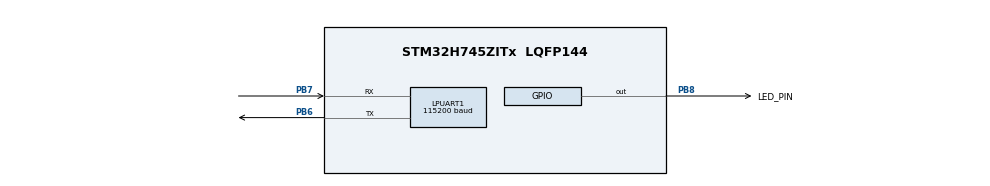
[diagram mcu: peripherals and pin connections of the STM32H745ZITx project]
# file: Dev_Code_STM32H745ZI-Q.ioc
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CORTEX_M7.default_mode_Activation=1
CortexM4.IPs=FATFS_M4\:I,FREERTOS_M4\:I,IWDG2\:I,RCC,WWDG2\:I,DMA,BDMA,MDMA,NVIC2\:I,USART3,ETH,DEBUG,PDM2PCM_M4\:I,PWR,RESMGR_UTILITY,SYS_M4\:I,USB_DEVICE_M4\:I,USB_HOST_M4\:I,CORTEX_M4\:I,GPIO,OPENAMP_M4\:I,VREFBUF,NUCLEO-H745ZI-Q\:I
CortexM7.IPs=FATFS_M7\:I,FREERTOS_M7\:I,IWDG1\:I,RCC\:I,WWDG1\:I,DMA\:I,BDMA\:I,MDMA\:I,NVIC1\:I,SYS\:I,USART3\:I,USB_OTG_FS\:I,ETH\:I,CORTEX_M7\:I,DEBUG\:I,PDM2PCM_M7\:I,PWR\:I,RESMGR_UTILITY\:I,USB_DEVICE_M7\:I,USB_HOST_M7\:I,GPIO\:I,OPENAMP_M7\:I,VREFBUF\:I,LPUART1\:I
CortexM7.Pins=PB8
LPUART1.BaudRate=115200
Mcu.Family=STM32H7
Mcu.Name=STM32H745ZITx
Mcu.Package=LQFP144
NUCLEO-H745ZI-Q.BUTTON=1
NUCLEO-H745ZI-Q.Bsp_Common_DEMO=true
NUCLEO-H745ZI-Q.LD1=true
NUCLEO-H745ZI-Q.LD2=true
NUCLEO-H745ZI-Q.LD3=true
NUCLEO-H745ZI-Q.VCP=true
NVIC1.PriorityGroup=NVIC_PRIORITYGROUP_4
NVIC2.EXTI15_10_IRQn=true\:0\:0\:false\:false\:true\:false\:true\:true
NVIC2.PriorityGroup=NVIC_PRIORITYGROUP_4
PB6.Mode=Asynchronous
PB6.PinAttribute=CortexM7
PB6.Signal=LPUART1_TX
PB7.Mode=Asynchronous
PB7.PinAttribute=CortexM7
PB7.Signal=LPUART1_RX
PB8.GPIO_Label=LED_PIN
PB8.GPIO_ModeDefaultOutputPP=GPIO_MODE_OUTPUT_PP
PB8.PinAttribute=CortexM7
PB8.PinState=GPIO_PIN_RESET
PB8.Signal=GPIO_Output
PC14-OSC32_IN\ (OSC32_IN).PinAttribute=Free
PC14-OSC32_IN\ (OSC32_IN).Signal=RCC_OSC32_IN
PC15-OSC32_OUT\ (OSC32_OUT).PinAttribute=Free
PC15-OSC32_OUT\ (OSC32_OUT).Signal=RCC_OSC32_OUT
PD8.Signal=USART3_TX
PD9.Signal=USART3_RX
PH0-OSC_IN\ (PH0).PinAttribute=Free
PH0-OSC_IN\ (PH0).Signal=RCC_OSC_IN
PH1-OSC_OUT\ (PH1).PinAttribute=Free
PH1-OSC_OUT\ (PH1).Signal=RCC_OSC_OUT
ProjectManager.HeapSize=M4-0x200,M7-0x200
ProjectManager.StackSize=M4-0x400,M7-0x400
ProjectManager.TargetToolchain=STM32CubeIDE
RCC.ADCFreq_Value=129000000
RCC.APB1Freq_Value=64000000
RCC.APB2Freq_Value=64000000
RCC.APB3Freq_Value=32000000
RCC.APB4Freq_Value=64000000
RCC.CortexFreq_Value=64000000
RCC.D1PPRE=RCC_APB3_DIV2
RCC.DIVM1=18
RCC.DIVM3=22
RCC.DIVN3=169
RCC.DIVQ3=4
RCC.HCLKFreq_Value=64000000
RCC.PLL2FRACN=0
RCC.PLL3FRACN=0
RCC.PLLFRACN=0
RCC.SYSCLKFreq_VALUE=64000000
RCC.SupplySource=PWR_DIRECT_SMPS_SUPPLY
RCC.USBCLockSelection=RCC_USBCLKSOURCE_PLL3
RCC.USBFreq_Value=122909090.9090909
VP_NUCLEO-H745ZI-Q_VS_BSP_COMMON.Mode=COMMON
VP_SYS_M4_VS_Systick.Mode=SysTick
board=NUCLEO-H745ZI-Q

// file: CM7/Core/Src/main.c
/* USER CODE BEGIN Header */
/**
  ******************************************************************************
  * @file           : main.c
  * @brief          : Main program body
  ******************************************************************************
  * @attention
  *
  * Copyright (c) 2026 STMicroelectronics.
  * All rights reserved.
  *
  * This software is licensed under terms that can be found in the LICENSE file
  * in the root directory of this software component.
  * If no LICENSE file comes with this software, it is provided AS-IS.
  *
  ******************************************************************************
  */
/* USER CODE END Header */
#include "main.h"

/* USER CODE BEGIN PD */

/* DUAL_CORE_BOOT_SYNC_SEQUENCE: Define for dual core boot synchronization    */
/*                             demonstration code based on hardware semaphore */
/* This define is present in both CM7/CM4 projects                            */
/* To comment when developping/debugging on a single core                     */
#define DUAL_CORE_BOOT_SYNC_SEQUENCE

#if defined(DUAL_CORE_BOOT_SYNC_SEQUENCE)
#ifndef HSEM_ID_0
#define HSEM_ID_0 (0U) /* HW semaphore 0*/
#endif
#endif /* DUAL_CORE_BOOT_SYNC_SEQUENCE */

/* USER CODE END PD */

UART_HandleTypeDef hlpuart1;

uint8_t rx_buff[10]; // Buffer to store received data

char msg1[] = "I got your Message!\r\n";
char msg2[] = "I didn't get a message\r\n";

unsigned int LED_ON = 1;
unsigned int LED_OFF = 0;

void SystemClock_Config(void);
static void MPU_Config(void);
static void MX_GPIO_Init(void);
static void MX_LPUART1_UART_Init(void);

int main(void)
{

/* USER CODE BEGIN Boot_Mode_Sequence_0 */
#if defined(DUAL_CORE_BOOT_SYNC_SEQUENCE)
  int32_t timeout;
#endif /* DUAL_CORE_BOOT_SYNC_SEQUENCE */
/* USER CODE END Boot_Mode_Sequence_0 */

  /* MPU Configuration--------------------------------------------------------*/
  MPU_Config();

/* USER CODE BEGIN Boot_Mode_Sequence_1 */
#if defined(DUAL_CORE_BOOT_SYNC_SEQUENCE)
  /* Wait until CPU2 boots and enters in stop mode or timeout*/
  timeout = 0xFFFF;
  while((__HAL_RCC_GET_FLAG(RCC_FLAG_D2CKRDY) != RESET) && (timeout-- > 0));
  if ( timeout < 0 )
  {
  Error_Handler();
  }
#endif /* DUAL_CORE_BOOT_SYNC_SEQUENCE */
/* USER CODE END Boot_Mode_Sequence_1 */
  /* MCU Configuration--------------------------------------------------------*/

  /* Reset of all peripherals, Initializes the Flash interface and the Systick. */
  HAL_Init();

  /* Configure the system clock */
  SystemClock_Config();
/* USER CODE BEGIN Boot_Mode_Sequence_2 */
#if defined(DUAL_CORE_BOOT_SYNC_SEQUENCE)
/* When system initialization is finished, Cortex-M7 will release Cortex-M4 by means of
HSEM notification */
/*HW semaphore Clock enable*/
__HAL_RCC_HSEM_CLK_ENABLE();
/*Take HSEM */
HAL_HSEM_FastTake(HSEM_ID_0);
/*Release HSEM in order to notify the CPU2(CM4)*/
HAL_HSEM_Release(HSEM_ID_0,0);
/* wait until CPU2 wakes up from stop mode */
timeout = 0xFFFF;
while((__HAL_RCC_GET_FLAG(RCC_FLAG_D2CKRDY) == RESET) && (timeout-- > 0));
if ( timeout < 0 )
{
Error_Handler();
}
#endif /* DUAL_CORE_BOOT_SYNC_SEQUENCE */
/* USER CODE END Boot_Mode_Sequence_2 */

  /* Initialize all configured peripherals */
  MX_GPIO_Init();
  MX_LPUART1_UART_Init();

  /* USER CODE BEGIN 2 */

  GPIO_InitTypeDef GPIO_InitStruct = {0};
  GPIO_InitStruct.Pin = GPIO_PIN_8;           // Change pin as needed
  GPIO_InitStruct.Mode = GPIO_MODE_OUTPUT_PP;
  GPIO_InitStruct.Pull = GPIO_NOPULL;
  GPIO_InitStruct.Speed = GPIO_SPEED_FREQ_LOW;
  HAL_GPIO_Init(GPIOB, &GPIO_InitStruct);     // Change port as needed

//  HAL_GPIO_WritePin(LED_PIN_GPIO_Port, LED_PIN_Pin, 1);

  /* USER CODE END 2 */

  /* Infinite loop */
  /* USER CODE BEGIN WHILE */
  while (1)
  {
//	if (HAL_UART_Receive(&hlpuart1, rx_buff, 10, HAL_MAX_DELAY) == HAL_OK){
//
////		HAL_GPIO_TogglePin(LED_PIN_GPIO_Port, LED_PIN_Pin);
//		HAL_GPIO_WritePin(LED_PIN_GPIO_Port, LED_PIN_Pin, 1);
//
////	     HAL_UART_Transmit(&huartX, rx_buff, 10, HAL_MAX_DELAY);
//
////		HAL_UART_Transmit(&hlpuart1, (uint8_t*)msg1, strlen(msg1), HAL_MAX_DELAY);
//
//
//	}
//	else{

//  }

	HAL_GPIO_WritePin(LED_PIN_GPIO_Port, LED_PIN_Pin, 1);

	HAL_UART_Transmit(&hlpuart1, (uint8_t*)"1\r\n", 3, HAL_MAX_DELAY);

	HAL_Delay(100);

	HAL_UART_Transmit(&hlpuart1, (uint8_t*)"0\r\n", 3, HAL_MAX_DELAY);

	HAL_GPIO_WritePin(LED_PIN_GPIO_Port, LED_PIN_Pin, 0);

	HAL_Delay(100);

//	 CppMain();// will run until the CppMain code returns from the loop in which will return to here and then terminate the program completely.
////
//

    /* USER CODE END WHILE */

  }
}

void SystemClock_Config(void)
{
  RCC_OscInitTypeDef RCC_OscInitStruct = {0};
  RCC_ClkInitTypeDef RCC_ClkInitStruct = {0};

  /** Supply configuration update enable
  */
  HAL_PWREx_ConfigSupply(PWR_DIRECT_SMPS_SUPPLY);

  /** Configure the main internal regulator output voltage
  */
  __HAL_PWR_VOLTAGESCALING_CONFIG(PWR_REGULATOR_VOLTAGE_SCALE3);

  while(!__HAL_PWR_GET_FLAG(PWR_FLAG_VOSRDY)) {}

  /** Initializes the RCC Oscillators according to the specified parameters
  * in the RCC_OscInitTypeDef structure.
  */
  RCC_OscInitStruct.OscillatorType = RCC_OSCILLATORTYPE_HSI;
  RCC_OscInitStruct.HSIState = RCC_HSI_DIV1;
  RCC_OscInitStruct.HSICalibrationValue = RCC_HSICALIBRATION_DEFAULT;
  RCC_OscInitStruct.PLL.PLLState = RCC_PLL_NONE;
  if (HAL_RCC_OscConfig(&RCC_OscInitStruct) != HAL_OK)
  {
    Error_Handler();
  }

  /** Initializes the CPU, AHB and APB buses clocks
  */
  RCC_ClkInitStruct.ClockType = RCC_CLOCKTYPE_HCLK|RCC_CLOCKTYPE_SYSCLK
                              |RCC_CLOCKTYPE_PCLK1|RCC_CLOCKTYPE_PCLK2
                              |RCC_CLOCKTYPE_D3PCLK1|RCC_CLOCKTYPE_D1PCLK1;
  RCC_ClkInitStruct.SYSCLKSource = RCC_SYSCLKSOURCE_HSI;
  RCC_ClkInitStruct.SYSCLKDivider = RCC_SYSCLK_DIV1;
  RCC_ClkInitStruct.AHBCLKDivider = RCC_HCLK_DIV1;
  RCC_ClkInitStruct.APB3CLKDivider = RCC_APB3_DIV2;
  RCC_ClkInitStruct.APB1CLKDivider = RCC_APB1_DIV1;
  RCC_ClkInitStruct.APB2CLKDivider = RCC_APB2_DIV1;
  RCC_ClkInitStruct.APB4CLKDivider = RCC_APB4_DIV1;

  if (HAL_RCC_ClockConfig(&RCC_ClkInitStruct, FLASH_LATENCY_1) != HAL_OK)
  {
    Error_Handler();
  }
}

static void MX_LPUART1_UART_Init(void)
{

  hlpuart1.Instance = LPUART1;
  hlpuart1.Init.BaudRate = 115200;
  hlpuart1.Init.WordLength = UART_WORDLENGTH_8B;
  hlpuart1.Init.StopBits = UART_STOPBITS_1;
  hlpuart1.Init.Parity = UART_PARITY_NONE;
  hlpuart1.Init.Mode = UART_MODE_TX_RX;
  hlpuart1.Init.HwFlowCtl = UART_HWCONTROL_NONE;
  hlpuart1.Init.OneBitSampling = UART_ONE_BIT_SAMPLE_DISABLE;
  hlpuart1.Init.ClockPrescaler = UART_PRESCALER_DIV1;
  hlpuart1.AdvancedInit.AdvFeatureInit = UART_ADVFEATURE_NO_INIT;
  hlpuart1.FifoMode = UART_FIFOMODE_DISABLE;
  if (HAL_UART_Init(&hlpuart1) != HAL_OK)
  {
    Error_Handler();
  }
  if (HAL_UARTEx_SetTxFifoThreshold(&hlpuart1, UART_TXFIFO_THRESHOLD_1_8) != HAL_OK)
  {
    Error_Handler();
  }
  if (HAL_UARTEx_SetRxFifoThreshold(&hlpuart1, UART_RXFIFO_THRESHOLD_1_8) != HAL_OK)
  {
    Error_Handler();
  }
  if (HAL_UARTEx_DisableFifoMode(&hlpuart1) != HAL_OK)
  {
    Error_Handler();
  }

}

static void MX_GPIO_Init(void)
{
  GPIO_InitTypeDef GPIO_InitStruct = {0};

  /* GPIO Ports Clock Enable */
  __HAL_RCC_GPIOB_CLK_ENABLE();

  /*Configure GPIO pin Output Level */
  HAL_GPIO_WritePin(LED_PIN_GPIO_Port, LED_PIN_Pin, GPIO_PIN_RESET);

  /*Configure GPIO pin : LED_PIN_Pin */
  GPIO_InitStruct.Pin = LED_PIN_Pin;
  GPIO_InitStruct.Mode = GPIO_MODE_OUTPUT_PP;
  GPIO_InitStruct.Pull = GPIO_NOPULL;
  GPIO_InitStruct.Speed = GPIO_SPEED_FREQ_LOW;
  HAL_GPIO_Init(LED_PIN_GPIO_Port, &GPIO_InitStruct);

}

 /* MPU Configuration */

void MPU_Config(void)
{
  MPU_Region_InitTypeDef MPU_InitStruct = {0};

  /* Disables the MPU */
  HAL_MPU_Disable();

  /** Initializes and configures the Region and the memory to be protected
  */
  MPU_InitStruct.Enable = MPU_REGION_ENABLE;
  MPU_InitStruct.Number = MPU_REGION_NUMBER0;
  MPU_InitStruct.BaseAddress = 0x0;
  MPU_InitStruct.Size = MPU_REGION_SIZE_4GB;
  MPU_InitStruct.SubRegionDisable = 0x87;
  MPU_InitStruct.TypeExtField = MPU_TEX_LEVEL0;
  MPU_InitStruct.AccessPermission = MPU_REGION_NO_ACCESS;
  MPU_InitStruct.DisableExec = MPU_INSTRUCTION_ACCESS_DISABLE;
  MPU_InitStruct.IsShareable = MPU_ACCESS_SHAREABLE;
  MPU_InitStruct.IsCacheable = MPU_ACCESS_NOT_CACHEABLE;
  MPU_InitStruct.IsBufferable = MPU_ACCESS_NOT_BUFFERABLE;

  HAL_MPU_ConfigRegion(&MPU_InitStruct);
  /* Enables the MPU */
  HAL_MPU_Enable(MPU_PRIVILEGED_DEFAULT);

}

void Error_Handler(void)
{
  __disable_irq();
  while (1)
  {
  }
}
